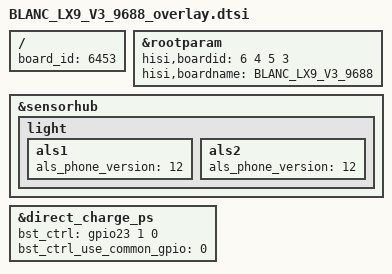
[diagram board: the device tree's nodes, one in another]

/**
 * Copyright (C) 2014 Hisilicon Ltd.
 *
 *  This program is free software; you can redistribute it and/or modify
 *  it under the terms of the GNU General Public License version 2 as
 *  publishhed by the Free Software Foundation.
 */

/include/ "BLANC_LX9_V1_overlay.dtsi"

/ {
	board_id = <6453>;
};

&rootparam {
    hisi,boardid = <6 4 5 3>;
    hisi,boardname = "BLANC_LX9_V3_9688";
};

	&sensorhub{
		light{
			als1{
				als_phone_version = <12>;
			};
			als2{
				als_phone_version = <12>;
			};
		};
	};

	&direct_charge_ps {
		bst_ctrl = <&gpio23 1 0>;
		bst_ctrl_use_common_gpio = <0>;
	};
